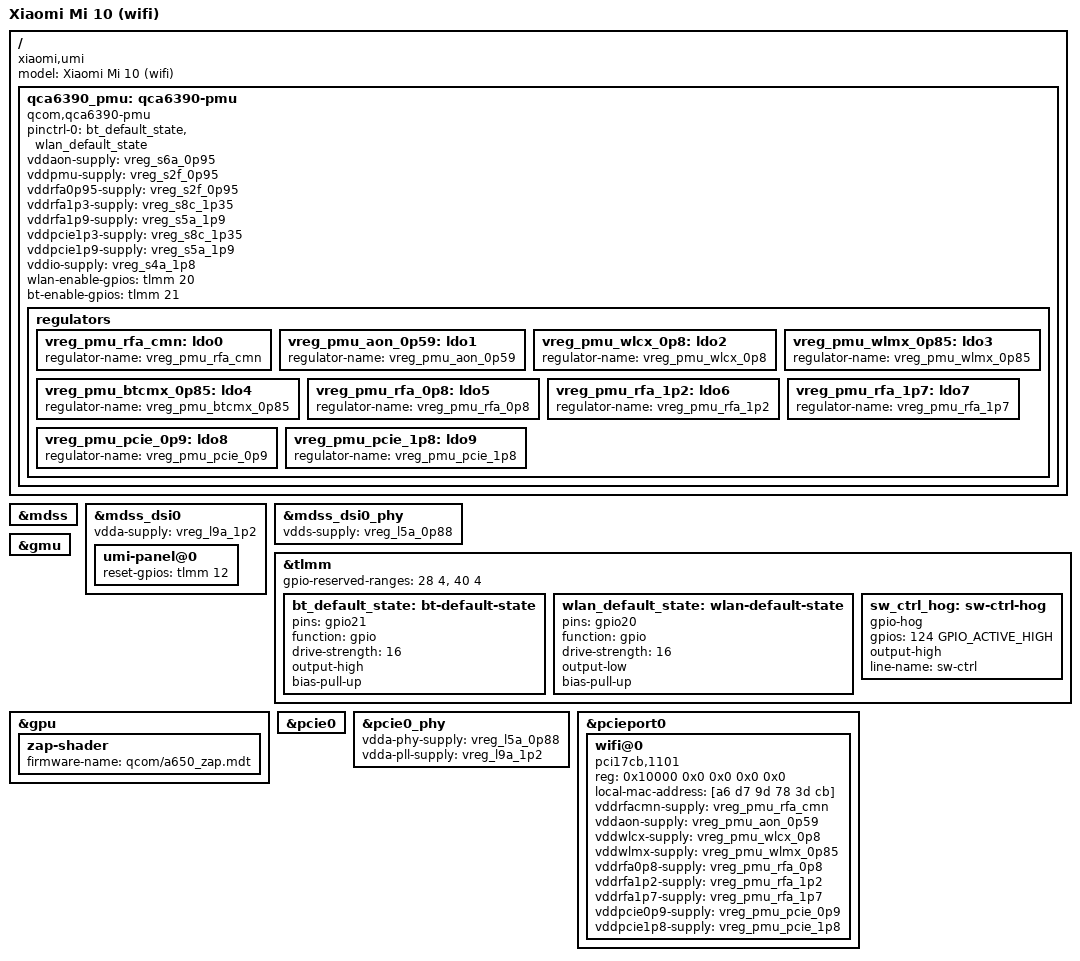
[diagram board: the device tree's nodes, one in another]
// SPDX-License-Identifier: BSD-3-Clause
/*
 * Xiaomi Mi 10 (umi) — 显示/触摸 + PCIe/QCA6390 WiFi
 *
 * ★ 这一版是**照抄作者 Armbian 镜像里的 dtb**（7.2.7-current-sm8250）反编译出来的配置。
 *   从他镜像里 dump 出来的关键差异，解释了为什么我们 6.12 上怎么试都不行：
 *
 *   1. 他的 gpio-reserved-ranges **只有两段**：
 *          gpio-reserved-ranges = <28 4>, <40 4>;
 *      也就是说 NORTH tile 的 gpio20/21/79/81 **全是可用的**。
 *      而我们在 6.12 上把 NORTH 整片保留，还在 7.2.12 上撞到
 *      gpiochip_setup_shared -EINVAL —— 怀疑 7.2.x 已经修了 NORTH 的访问问题。
 *
 *   2. pcie0 保留主线给的 pinctrl-0 / perst-gpios / wake-gpios，一个都没删：
 *          perst-gpios = <&tlmm 79 GPIO_ACTIVE_LOW>;
 *          wake-gpios  = <&tlmm 81 GPIO_ACTIVE_HIGH>;
 *          pinctrl-0   = <&pcie0_default_state>;
 *
 *   3. qca6390-pmu 带 pinctrl-0 指向 wlan/bt 的 default state，
 *      并且同时有 wlan-enable-gpios / bt-enable-gpios：
 *          wlan-default-state { pins = "gpio20"; function = "gpio";
 *                               drive-strength = <16>; output-low; bias-pull-up; };
 *          bt-default-state   { pins = "gpio21"; function = "gpio";
 *                               drive-strength = <16>; output-high; bias-pull-up; };
 *      注意 wlan 是 output-low —— 上电靠 pwrseq 驱动 power_on 时拉高。
 *
 *   4. 子节点 regulators { ldo0..ldo9 } 保留着（新驱动不消费，但留着无害）。
 *
 * 所以这份 dts 是「作者的配置 + 我们的显示/触摸部分」。
 * 它需要 **7.2.x 内核**（7.2.7 是他验证过的版本，我们用 7.2.12）。
 */
/dts-v1/;

#include "sm8250-xiaomi-umi-common.dtsi"

/ {
	model = "Xiaomi Mi 10 (wifi)";
	compatible = "xiaomi,umi", "qcom,sm8250";

	qca6390_pmu: qca6390-pmu {
		compatible = "qcom,qca6390-pmu";

		pinctrl-names = "default";
		pinctrl-0 = <&bt_default_state>, <&wlan_default_state>;

		/* ★ 供电对应关系以 umi 的下游 DT（qcom,cnss-qca6390）为准：
		 *     vdd-wlan-aon  (.95V) = pm8150_s6   -> vddaon
		 *     vdd-wlan-dig  (.95V) = pm8009_s2   -> vddpmu / vddrfa0p95
		 *     vdd-wlan-io   (1.8V) = pm8150_s4   -> vddio
		 *     vdd-wlan-rfa1 (1.9V) = pm8150_s5   -> vddrfa1p9 / vddpcie1p9
		 *     vdd-wlan-rfa2 (1.35V)= pm8150a_s8  -> vddrfa1p3 / vddpcie1p3
		 *
		 * vddpmu / vddrfa0p95 **不能**接 vreg_s6a_0p95：那是 AON，不是
		 * digital。接到 S6A 的结果是 PM8009 S2 一个 consumer 都没有，
		 * regulator_summary 里长期是 `vreg_s2f_0p5  0 users  512mV`，
		 * QCA6390 的 PMU 数字域根本没电 —— 卡片在总线上永远 Detect.Quiet。*/
		vddaon-supply = <&vreg_s6a_0p95>;
		vddpmu-supply = <&vreg_s2f_0p95>;
		vddrfa0p95-supply = <&vreg_s2f_0p95>;
		vddrfa1p3-supply = <&vreg_s8c_1p35>;
		vddrfa1p9-supply = <&vreg_s5a_1p9>;
		vddpcie1p3-supply = <&vreg_s8c_1p35>;
		vddpcie1p9-supply = <&vreg_s5a_1p9>;
		vddio-supply = <&vreg_s4a_1p8>;

		wlan-enable-gpios = <&tlmm 20 GPIO_ACTIVE_HIGH>;
		bt-enable-gpios = <&tlmm 21 GPIO_ACTIVE_HIGH>;

		regulators {
			vreg_pmu_rfa_cmn: ldo0 { regulator-name = "vreg_pmu_rfa_cmn"; };
			vreg_pmu_aon_0p59: ldo1 { regulator-name = "vreg_pmu_aon_0p59"; };
			vreg_pmu_wlcx_0p8: ldo2 { regulator-name = "vreg_pmu_wlcx_0p8"; };
			vreg_pmu_wlmx_0p85: ldo3 { regulator-name = "vreg_pmu_wlmx_0p85"; };
			vreg_pmu_btcmx_0p85: ldo4 { regulator-name = "vreg_pmu_btcmx_0p85"; };
			vreg_pmu_rfa_0p8: ldo5 { regulator-name = "vreg_pmu_rfa_0p8"; };
			vreg_pmu_rfa_1p2: ldo6 { regulator-name = "vreg_pmu_rfa_1p2"; };
			vreg_pmu_rfa_1p7: ldo7 { regulator-name = "vreg_pmu_rfa_1p7"; };
			vreg_pmu_pcie_0p9: ldo8 { regulator-name = "vreg_pmu_pcie_0p9"; };
			vreg_pmu_pcie_1p8: ldo9 { regulator-name = "vreg_pmu_pcie_1p8"; };
		};
	};
};

/* ---------------------------------------------------------------- 显示子系统
 * 与基线完全一致，别删。*/
&mdss {
	status = "okay";
};

&mdss_dsi0 {
	vdda-supply = <&vreg_l9a_1p2>;
	status = "okay";
};

&mdss_dsi0_phy {
	vdds-supply = <&vreg_l5a_0p88>;
	status = "okay";
};

#include "xiaomi-umi-panels.dtsi"

&mdss_dsi0 {
	umi-panel@0 {
		reset-gpios = <&tlmm 12 GPIO_ACTIVE_HIGH>;
	};
};

#include "sm8250-xiaomi-umi-touch.dtsi"

/* 电量计 + 充电（PM8150B fg/smb5 + TI bq25970），见 docs/BATTERY.md */
#include "xiaomi-umi-battery.dtsi"

/* ------------------------------------------------------------ GPIO 保留区
 * 作者只保留 28-31 和 40-43。NORTH tile（20/21/79/81 所在）**全部放开**。
 * 这正是他那边 WiFi 能起来的前提。
 */
&tlmm {
	/delete-property/ gpio-reserved-ranges;
	gpio-reserved-ranges = <28 4>, <40 4>;

	bt_default_state: bt-default-state {
		pins = "gpio21";
		function = "gpio";
		drive-strength = <16>;
		output-high;
		bias-pull-up;
	};

	wlan_default_state: wlan-default-state {
		pins = "gpio20";
		function = "gpio";
		drive-strength = <16>;
		output-low;
		bias-pull-up;
	};

	/* 下游 DT 里有 qcom,sw-ctrl-gpio = <&tlmm 124>，cnss2 驱动只在
	 * PCIe link 恢复失败时把它当前电平打印出来做诊断，从来没主动写过。
	 * 既然 20/79/81 都验证可访问了，顺手把 124 也当开关试一把：
	 * 如果它是射频/电源的第三道门，这里拉高就可能让链路起来。
	 * 124 是 <92 33> 范围的最后一个引脚，已改成 <92 32> 单独放出。*/
	sw_ctrl_hog: sw-ctrl-hog {
		gpio-hog;
		gpios = <124 GPIO_ACTIVE_HIGH>;
		output-high;
		line-name = "sw-ctrl";
	};

	/* ★★ 这里**不再**用 gpio-hog 去抢 WLAN_EN。
	 *
	 * 之前的思路：WLAN_EN 必须早于 PCIe link training 拉高，而 pwrseq 要等
	 * wifi@0 枚举后才 power_on，于是用 gpio-hog 提前顶住 gpio20。
	 *
	 * 但实测 pwrseq 驱动直接挂了：
	 *     pwrseq-qcom_wcn qca6390-pmu: error -EBUSY: Failed to get the
	 *     WLAN enable GPIO
	 * 因为 pwrseq_qcom_wcn_probe() 里是
	 *     devm_gpiod_get_optional(dev, "wlan-enable", GPIOD_ASIS)
	 * hog 已经把这条线独占，别的 consumer 一律 -EBUSY。hog 存在，pwrseq
	 * 设备就永远不存在，我们的 early power-on 也就永远拿不到 pwrseq。
	 *
	 * 现在改由 pcie-qcom 的 early power-on（devm_pwrseq_get + power_on，
	 * 在 PERST# 释放之前）来拉高 WLAN_EN —— 正是 7.2 里
	 * pci_pwrctrl_power_on_devices() 的位置。所有权归 pwrseq，谁也不抢。*/
};

/* ---------------------------------------------------------------- GPU (Adreno 650)
 *
 * 和主 DTS 里那段完全一样。固件（a650_zap.mdt/.b00-.b02、a650_sqe.fw、
 * a650_gmu.bin）必须打进 initramfs —— adreno 是内建驱动，probe 发生在
 * rootfs 挂载之前，只放 /lib/firmware 会 -2。详见 docs/GPU.md。
 */
&gmu {
	status = "okay";
};

&gpu {
	status = "okay";

	zap-shader {
		firmware-name = "qcom/a650_zap.mdt";
	};
};

/* ------------------------------------------------------------- PCIe0 → QCA6390
 * ★ 一个属性都不删 —— 和作者的 dtb 一样原样用主线那套。
 *
 * 之前我把 pinctrl-0 / perst-gpios / wake-gpios 全删了，只留 gpiod 请求，
 * 结果是 "Phy link never came up"。问题在于 pinctrl-0 负责把 pin79/81 的
 * mux 切到 GPIO 功能；没有它，PERST# 即使 gpiod 写了值也可能不落到引脚上。
 * 作者那边是保留 pinctrl-0 = <&pcie0_default_state> 的。*/
&pcie0 {
	status = "okay";
};

&pcie0_phy {
	vdda-phy-supply = <&vreg_l5a_0p88>;
	vdda-pll-supply = <&vreg_l9a_1p2>;
	status = "okay";
};

&pcieport0 {
	wifi@0 {
		compatible = "pci17cb,1101";
		reg = <0x10000 0x0 0x0 0x0 0x0>;

		/*
		 * 固定 MAC：不打这个属性时，卡片固件每次开机都会现生成一个
		 * （实测 00:03:7f:12:e7:e7 / 89:89 / 19:19 / a5:a5 / 9c:9c），
		 * 路由器的转发/MAC 绑定规则就没法用。
		 *
		 * ath11k 在 ath11k_mac_register() 里会调
		 * device_get_mac_address(ab->dev, mac_addr)，只要这个属性存在就
		 * 会优先用它——QCA6390 是单 radio，ab->pdevs_macaddr_valid 永远
		 * 为 false（那一支要求 num_radios > 1），所以 DT 的值一定生效。
		 *
		 * 换 MAC 时只改这一行，然后重打包 boot.img。
		 */
		local-mac-address = [a6 d7 9d 78 3d cb];

		vddrfacmn-supply = <&vreg_pmu_rfa_cmn>;
		vddaon-supply = <&vreg_pmu_aon_0p59>;
		vddwlcx-supply = <&vreg_pmu_wlcx_0p8>;
		vddwlmx-supply = <&vreg_pmu_wlmx_0p85>;
		vddrfa0p8-supply = <&vreg_pmu_rfa_0p8>;
		vddrfa1p2-supply = <&vreg_pmu_rfa_1p2>;
		vddrfa1p7-supply = <&vreg_pmu_rfa_1p7>;
		vddpcie0p9-supply = <&vreg_pmu_pcie_0p9>;
		vddpcie1p8-supply = <&vreg_pmu_pcie_1p8>;
	};
};
